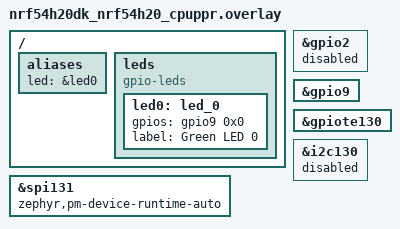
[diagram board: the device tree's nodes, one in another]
/*
 * Copyright (c) 2025 Nordic Semiconductor ASA
 *
 * SPDX-License-Identifier: LicenseRef-Nordic-5-Clause
 */

/ {
	aliases {
		led = &led0;
	};

	leds {
		compatible = "gpio-leds";

		led0: led_0 {
			gpios = <&gpio9 0x0 0x0>;
			label = "Green LED 0";
		};
	};
};

&gpio2 {
	status = "disabled";
};

&gpio9 {
	status = "okay";
};

&gpiote130 {
	status = "okay";
};

&i2c130 {
	status = "disabled";
};

&spi131 {
	zephyr,pm-device-runtime-auto;
};
